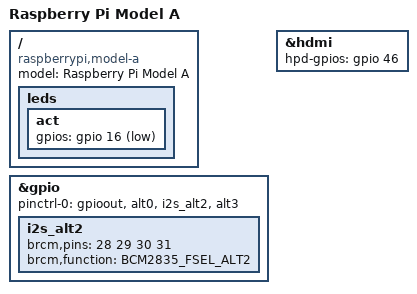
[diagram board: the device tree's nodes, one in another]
/dts-v1/;
#include "bcm2835.dtsi"
#include "bcm2835-rpi.dtsi"

/ {
	compatible = "raspberrypi,model-a", "brcm,bcm2835";
	model = "Raspberry Pi Model A";

	leds {
		act {
			gpios = <&gpio 16 1>;
		};
	};
};

&gpio {
	pinctrl-0 = <&gpioout &alt0 &i2s_alt2 &alt3>;

	/* I2S interface */
	i2s_alt2: i2s_alt2 {
		brcm,pins = <28 29 30 31>;
		brcm,function = <BCM2835_FSEL_ALT2>;
	};
};

&hdmi {
	hpd-gpios = <&gpio 46 GPIO_ACTIVE_HIGH>;
};
